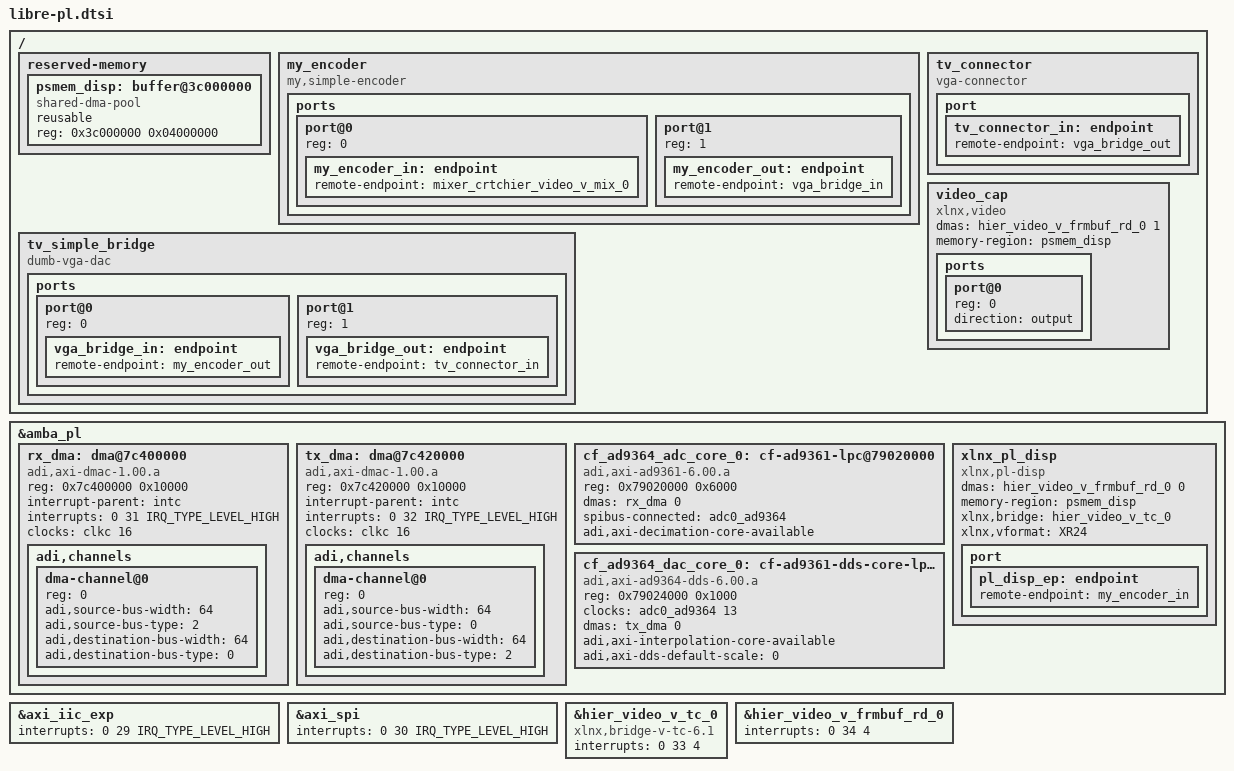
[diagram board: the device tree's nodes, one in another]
/*
 * SDTGen generates pl.dtsi with nodes for address space components in the block design.
 * Replace some of them with our custom nodes.
 */

&amba_pl {
	/delete-node/ axi_ad9361@79020000;
	/delete-node/ axi_dmac@7c400000;
	/delete-node/ axi_dmac@7c420000;

	rx_dma: dma@7c400000 {
		compatible = "adi,axi-dmac-1.00.a";
		reg = <0x7c400000 0x10000>;
		#dma-cells = <1>;
		interrupt-parent = <&intc>;
		interrupts = <0 31 IRQ_TYPE_LEVEL_HIGH>;
		clocks = <&clkc 16>;

		adi,channels {
			#size-cells = <0>;
			#address-cells = <1>;

			dma-channel@0 {
				reg = <0>;
				adi,source-bus-width = <64>;
				adi,source-bus-type = <2>;
				adi,destination-bus-width = <64>;
				adi,destination-bus-type = <0>;
			};
		};
	};

	tx_dma: dma@7c420000 {
		compatible = "adi,axi-dmac-1.00.a";
		reg = <0x7c420000 0x10000>;
		#dma-cells = <1>;
		interrupt-parent = <&intc>;
		interrupts = <0 32 IRQ_TYPE_LEVEL_HIGH>;
		clocks = <&clkc 16>;

		adi,channels {
			#size-cells = <0>;
			#address-cells = <1>;

			dma-channel@0 {
				reg = <0>;
				adi,source-bus-width = <64>;
				adi,source-bus-type = <0>;
				adi,destination-bus-width = <64>;
				adi,destination-bus-type = <2>;
			};
		};
	};

	cf_ad9364_adc_core_0: cf-ad9361-lpc@79020000 {
		compatible = "adi,axi-ad9361-6.00.a";
		reg = <0x79020000 0x6000>;
		dmas = <&rx_dma 0>;
		dma-names = "rx";
		spibus-connected = <&adc0_ad9364>;
		adi,axi-decimation-core-available;
	};

	cf_ad9364_dac_core_0: cf-ad9361-dds-core-lpc@79024000 {
		compatible = "adi,axi-ad9364-dds-6.00.a";
		reg = <0x79024000 0x1000>;
		clocks = <&adc0_ad9364 13>;
		clock-names = "sampl_clk";
		dmas = <&tx_dma 0>;
		dma-names = "tx";
		adi,axi-interpolation-core-available;
		adi,axi-dds-default-scale = <0>;
	};
};

// SDTGen assigns the wrong interrupt number (broken xlconcat/ilconcat traversal)
// and for AXI SPI it generates the wrong type (I think): IRQ_TYPE_EDGE_RISING
&axi_iic_exp {
	interrupts = <0 29 IRQ_TYPE_LEVEL_HIGH>;
};
&axi_spi {
	interrupts = <0 30 IRQ_TYPE_LEVEL_HIGH>;
};

&hier_video_v_tc_0 {
	//compatible = "xlnx,v-tc-6.1", "xlnx,bridge-v-tc-6.1";
	/* don't let the xilinx-vtc driver from the media framework bind, only xlnx-vtc from DRM */
	compatible = "xlnx,bridge-v-tc-6.1";
	//compatible = "xlnx,v-tc-6.2", "xlnx,bridge-v-tc-6.1";
	interrupts = < 0 33 4 >;
};

&hier_video_v_frmbuf_rd_0 {
	interrupts = < 0 34 4 >;
};

&amba_pl {
	xlnx_pl_disp {
		compatible = "xlnx,pl-disp";
		dmas = <&hier_video_v_frmbuf_rd_0 0>;
		dma-names = "dma0";
		memory-region = <&psmem_disp>;
		xlnx,bridge = <&hier_video_v_tc_0>;
		xlnx,vformat = "XR24";
		port {
			pl_disp_ep: endpoint {
				remote-endpoint = <&my_encoder_in>;
			};
		};
	};
};

/ {
	reserved-memory {
		#address-cells = <0x1>;
		#size-cells = <0x1>;
		ranges;
		psmem_disp: buffer@3c000000 {
			compatible = "shared-dma-pool";
			reusable;
			reg = <0x3c000000 0x04000000>;
		};
	};

	my_encoder {
		compatible = "my,simple-encoder";

		ports {
			#address-cells = <1>;
			#size-cells = <0>;

			port@0 {
				reg = <0>;

				my_encoder_in: endpoint {
					remote-endpoint = <&mixer_crtchier_video_v_mix_0>;
				};
			};

			port@1 {
				reg = <1>;

				my_encoder_out: endpoint {
					remote-endpoint = <&vga_bridge_in>;
				};
			};
		};
	};

	tv_simple_bridge {
		compatible = "dumb-vga-dac";

		ports {
			#address-cells = <1>;
			#size-cells = <0>;

			port@0 {
				reg = <0>;

				vga_bridge_in: endpoint {
					remote-endpoint = <&my_encoder_out>;
				};
			};

			port@1 {
				reg = <1>;

				vga_bridge_out: endpoint {
					remote-endpoint = <&tv_connector_in>;
				};
			};
		};
	};

	tv_connector {
		compatible = "vga-connector";

		port {
			tv_connector_in: endpoint {
				remote-endpoint = <&vga_bridge_out>;
			};
		};
	};

	video_cap {
		compatible = "xlnx,video";
		dmas = <&hier_video_v_frmbuf_rd_0 1>;
		dma-names = "port0";
		memory-region = <&psmem_disp>;

		ports {
			#address-cells = <1>;
			#size-cells = <0>;

			port@0 {
				reg = <0>;
				direction = "output";
			};
		};
	};
};
